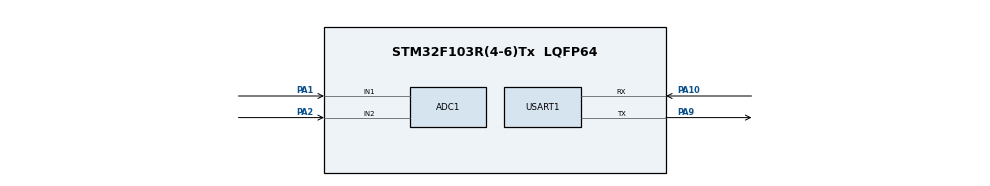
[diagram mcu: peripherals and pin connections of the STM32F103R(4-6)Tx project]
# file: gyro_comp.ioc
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ADC1.Channel-5\#ChannelRegularConversion=ADC_CHANNEL_1
ADC1.Channel-6\#ChannelRegularConversion=ADC_CHANNEL_2
ADC1.NbrOfConversion=2
ADC1.NbrOfConversionFlag=1
ADC1.Rank-5\#ChannelRegularConversion=1
ADC1.Rank-6\#ChannelRegularConversion=2
ADC1.SamplingTime-5\#ChannelRegularConversion=ADC_SAMPLETIME_55CYCLES_5
ADC1.SamplingTime-6\#ChannelRegularConversion=ADC_SAMPLETIME_55CYCLES_5
ADC1.master=1
Dma.ADC1.0.Direction=DMA_PERIPH_TO_MEMORY
Dma.ADC1.0.Instance=DMA1_Channel1
Dma.ADC1.0.MemDataAlignment=DMA_MDATAALIGN_WORD
Dma.ADC1.0.MemInc=DMA_MINC_ENABLE
Dma.ADC1.0.Mode=DMA_NORMAL
Dma.ADC1.0.PeriphDataAlignment=DMA_PDATAALIGN_WORD
Dma.ADC1.0.PeriphInc=DMA_PINC_DISABLE
Dma.ADC1.0.Priority=DMA_PRIORITY_MEDIUM
Dma.Request0=ADC1
Mcu.Family=STM32F1
Mcu.Name=STM32F103R(4-6)Tx
Mcu.Package=LQFP64
NVIC.DMA1_Channel1_IRQn=true\:0\:0\:false\:false\:true\:false\:true
NVIC.PriorityGroup=NVIC_PRIORITYGROUP_4
NVIC.USART1_IRQn=true\:0\:0\:false\:false\:true\:true\:true
PA1.Signal=ADCx_IN1
PA10.Mode=Asynchronous
PA10.Signal=USART1_RX
PA2.Signal=ADCx_IN2
PA9.Mode=Asynchronous
PA9.Signal=USART1_TX
ProjectManager.HeapSize=0x200
ProjectManager.StackSize=0x400
ProjectManager.TargetToolchain=MDK-ARM V5.27
RCC.APB1Freq_Value=8000000
RCC.APB2Freq_Value=8000000
SH.ADCx_IN1.0=ADC1_IN1,IN1
SH.ADCx_IN2.0=ADC1_IN2,IN2
USART1.VirtualMode=VM_ASYNC
VP_SYS_VS_ND.Mode=No_Debug
board=custom

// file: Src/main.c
/* USER CODE BEGIN Header */
/**
  ******************************************************************************
  * @file           : main.c
  * @brief          : Main program body
  ******************************************************************************
  * @attention
  *
  * <h2><center>&copy; Copyright (c) 2020 STMicroelectronics.
  * All rights reserved.</center></h2>
  *
  * This software component is licensed by ST under BSD 3-Clause license,
  * the "License"; You may not use this file except in compliance with the
  * License. You may obtain a copy of the License at:
  *                        opensource.org/licenses/BSD-3-Clause
  *
  ******************************************************************************
  */
/* USER CODE END Header */

#include "main.h"
#include "stdio.h"
#include "string.h"

ADC_HandleTypeDef hadc1;
DMA_HandleTypeDef hdma_adc1;

UART_HandleTypeDef huart1;

void SystemClock_Config(void);
static void MX_GPIO_Init(void);
static void MX_DMA_Init(void);
static void MX_ADC1_Init(void);
static void MX_USART1_UART_Init(void);

/* USER CODE BEGIN 0 */
uint32_t data[2];
uint32_t adc_buffer[2];
char speed[32] = " ";
char direction[32] = " ";
char info[64] = " ";
/* USER CODE END 0 */

void HAL_ADC_ConvCpltCallback(ADC_HandleTypeDef* hadc){

	if(hadc->Instance == ADC1){
		data[0] = adc_buffer[0];
		data[1] = adc_buffer[1];
	}
}

int main(void)
{

  /* MCU Configuration--------------------------------------------------------*/

  /* Reset of all peripherals, Initializes the Flash interface and the Systick. */
  HAL_Init();

  /* Configure the system clock */
  SystemClock_Config();

  /* Initialize all configured peripherals */
  MX_GPIO_Init();
  MX_DMA_Init();
  MX_ADC1_Init();
  MX_USART1_UART_Init();

  /* USER CODE BEGIN 2 */
  HAL_UART_Init(&huart1);
  /* USER CODE END 2 */

  /* Infinite loop */
  /* USER CODE BEGIN WHILE */

  while (1)
  {
		/*HAL_ADC_Start_DMA(&hadc1, adc_buffer, 2);

		sprintf(speed, "speed:%d", data[0]);
		HAL_UART_Transmit(&huart1, (uint8_t*)&speed, sizeof(speed), HAL_MAX_DELAY);
		HAL_Delay(1000);

		sprintf(direction, "direction:%d", data[1]);
		HAL_UART_Transmit(&huart1, (uint8_t*)&direction, sizeof(direction), HAL_MAX_DELAY);
		HAL_Delay(1000);*/
		HAL_ADC_Start_DMA(&hadc1, adc_buffer, 2);
		//sprintf(speed, "speed:%d-", data[0]);
		//sprintf(direction, "direction:%d", data[1]);
		data[0] = (1000*data[0]+4096000)/4096;
		data[1] = (1000*data[1]+4096000)/4096;
		sprintf(speed, "%d-", data[0]);
		sprintf(direction, "%d", data[1]);
		strcat(info, speed);
		strcat(info, direction);
		HAL_UART_Transmit(&huart1, (uint8_t*)&info, sizeof(info), HAL_MAX_DELAY);
		HAL_Delay(1000);
		strcpy(info, "");

  }
}

void SystemClock_Config(void)
{
  RCC_OscInitTypeDef RCC_OscInitStruct = {0};
  RCC_ClkInitTypeDef RCC_ClkInitStruct = {0};
  RCC_PeriphCLKInitTypeDef PeriphClkInit = {0};

  /** Initializes the CPU, AHB and APB busses clocks
  */
  RCC_OscInitStruct.OscillatorType = RCC_OSCILLATORTYPE_HSI;
  RCC_OscInitStruct.HSIState = RCC_HSI_ON;
  RCC_OscInitStruct.HSICalibrationValue = RCC_HSICALIBRATION_DEFAULT;
  RCC_OscInitStruct.PLL.PLLState = RCC_PLL_NONE;
  if (HAL_RCC_OscConfig(&RCC_OscInitStruct) != HAL_OK)
  {
    Error_Handler();
  }
  /** Initializes the CPU, AHB and APB busses clocks
  */
  RCC_ClkInitStruct.ClockType = RCC_CLOCKTYPE_HCLK|RCC_CLOCKTYPE_SYSCLK
                              |RCC_CLOCKTYPE_PCLK1|RCC_CLOCKTYPE_PCLK2;
  RCC_ClkInitStruct.SYSCLKSource = RCC_SYSCLKSOURCE_HSI;
  RCC_ClkInitStruct.AHBCLKDivider = RCC_SYSCLK_DIV1;
  RCC_ClkInitStruct.APB1CLKDivider = RCC_HCLK_DIV1;
  RCC_ClkInitStruct.APB2CLKDivider = RCC_HCLK_DIV1;

  if (HAL_RCC_ClockConfig(&RCC_ClkInitStruct, FLASH_LATENCY_0) != HAL_OK)
  {
    Error_Handler();
  }
  PeriphClkInit.PeriphClockSelection = RCC_PERIPHCLK_ADC;
  PeriphClkInit.AdcClockSelection = RCC_ADCPCLK2_DIV2;
  if (HAL_RCCEx_PeriphCLKConfig(&PeriphClkInit) != HAL_OK)
  {
    Error_Handler();
  }
}

static void MX_ADC1_Init(void)
{

  ADC_ChannelConfTypeDef sConfig = {0};

  /** Common config
  */
  hadc1.Instance = ADC1;
  hadc1.Init.ScanConvMode = ADC_SCAN_ENABLE;
  hadc1.Init.ContinuousConvMode = DISABLE;
  hadc1.Init.DiscontinuousConvMode = DISABLE;
  hadc1.Init.ExternalTrigConv = ADC_SOFTWARE_START;
  hadc1.Init.DataAlign = ADC_DATAALIGN_RIGHT;
  hadc1.Init.NbrOfConversion = 2;
  if (HAL_ADC_Init(&hadc1) != HAL_OK)
  {
    Error_Handler();
  }
  /** Configure Regular Channel
  */
  sConfig.Channel = ADC_CHANNEL_1;
  sConfig.Rank = ADC_REGULAR_RANK_1;
  sConfig.SamplingTime = ADC_SAMPLETIME_55CYCLES_5;
  if (HAL_ADC_ConfigChannel(&hadc1, &sConfig) != HAL_OK)
  {
    Error_Handler();
  }
  /** Configure Regular Channel
  */
  sConfig.Channel = ADC_CHANNEL_2;
  sConfig.Rank = ADC_REGULAR_RANK_2;
  if (HAL_ADC_ConfigChannel(&hadc1, &sConfig) != HAL_OK)
  {
    Error_Handler();
  }

}

static void MX_USART1_UART_Init(void)
{

  huart1.Instance = USART1;
  huart1.Init.BaudRate = 115200;
  huart1.Init.WordLength = UART_WORDLENGTH_8B;
  huart1.Init.StopBits = UART_STOPBITS_1;
  huart1.Init.Parity = UART_PARITY_NONE;
  huart1.Init.Mode = UART_MODE_TX_RX;
  huart1.Init.HwFlowCtl = UART_HWCONTROL_NONE;
  huart1.Init.OverSampling = UART_OVERSAMPLING_16;
  if (HAL_UART_Init(&huart1) != HAL_OK)
  {
    Error_Handler();
  }

}

static void MX_DMA_Init(void)
{

  /* DMA controller clock enable */
  __HAL_RCC_DMA1_CLK_ENABLE();

  /* DMA interrupt init */
  /* DMA1_Channel1_IRQn interrupt configuration */
  HAL_NVIC_SetPriority(DMA1_Channel1_IRQn, 0, 0);
  HAL_NVIC_EnableIRQ(DMA1_Channel1_IRQn);

}

static void MX_GPIO_Init(void)
{

  /* GPIO Ports Clock Enable */
  __HAL_RCC_GPIOA_CLK_ENABLE();

}

void Error_Handler(void)
{
}

/************************ (C) COPYRIGHT STMicroelectronics *****END OF FILE****/
